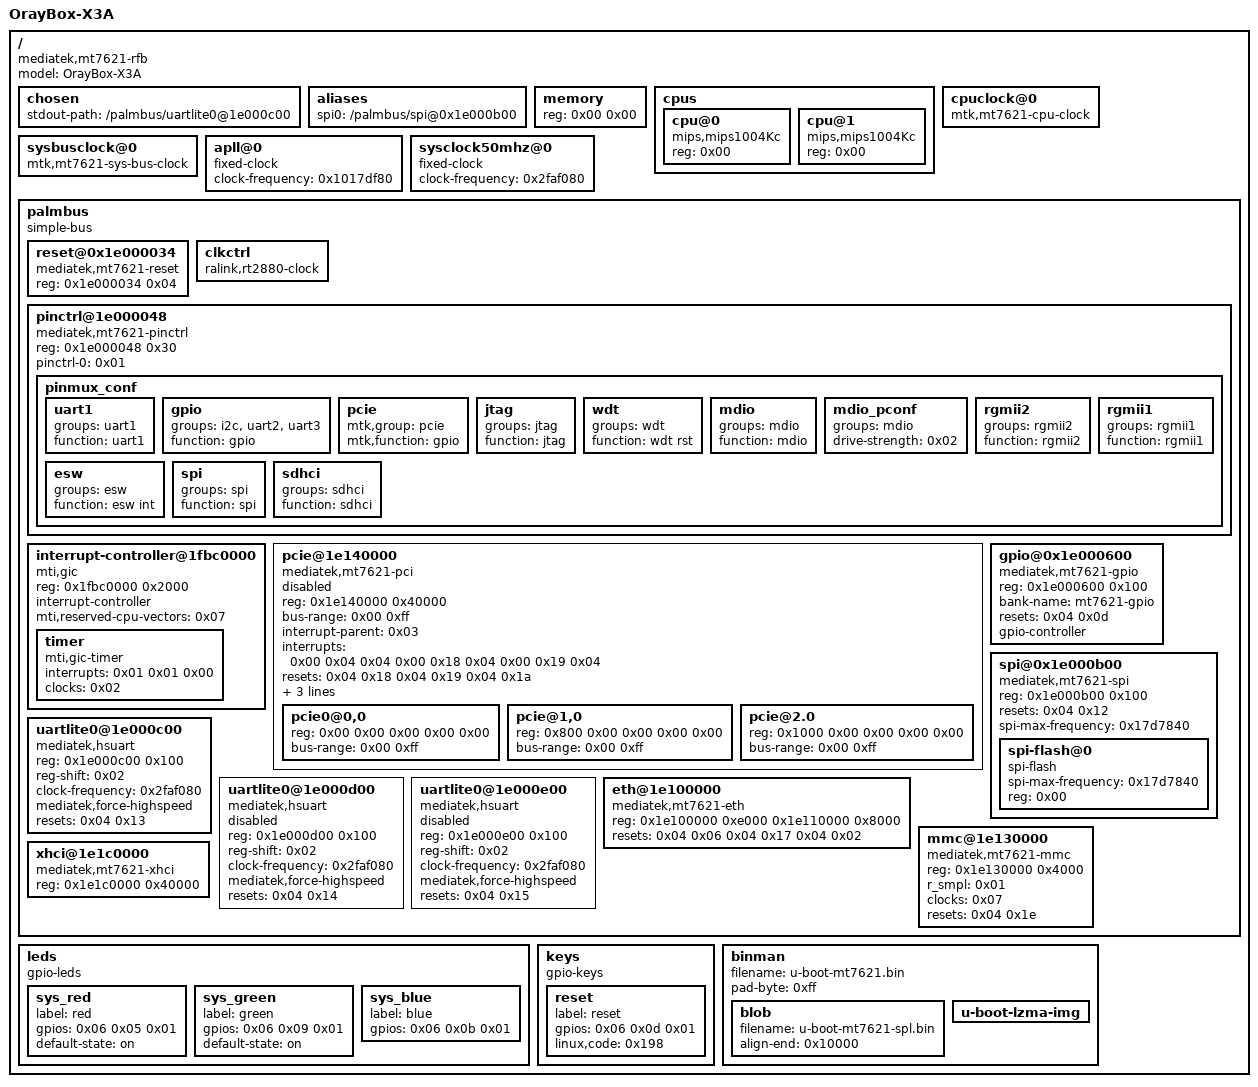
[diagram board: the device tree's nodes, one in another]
/dts-v1/;

/ {
	#address-cells = <0x01>;
	#size-cells = <0x01>;
	compatible = "mediatek,mt7621-rfb", "mediatek,mt7621-soc";
	model = "OrayBox-X3A";

	chosen {
		stdout-path = "/palmbus/uartlite0@1e000c00";
	};

	aliases {
		spi0 = "/palmbus/spi@0x1e000b00";
	};

	memory {
		device_type = "memory";
		reg = <0x00 0x00>;
	};

	cpus {
		#address-cells = <0x01>;
		#size-cells = <0x00>;

		cpu@0 {
			device_type = "cpu";
			compatible = "mips,mips1004Kc";
			reg = <0x00>;
		};

		cpu@1 {
			device_type = "cpu";
			compatible = "mips,mips1004Kc";
			reg = <0x00>;
		};
	};

	cpuclock@0 {
		#clock-cells = <0x00>;
		compatible = "mtk,mt7621-cpu-clock";
		phandle = <0x02>;
	};

	sysbusclock@0 {
		#clock-cells = <0x00>;
		compatible = "mtk,mt7621-sys-bus-clock";
	};

	apll@0 {
		#clock-cells = <0x00>;
		compatible = "fixed-clock";
		clock-frequency = <0x1017df80>;
	};

	sysclock50mhz@0 {
		compatible = "fixed-clock";
		clock-frequency = <0x2faf080>;
		#clock-cells = <0x00>;
		phandle = <0x07>;
	};

	palmbus {
		compatible = "simple-bus";
		ranges;
		#address-cells = <0x01>;
		#size-cells = <0x01>;

		reset@0x1e000034 {
			compatible = "mediatek,mt7621-reset";
			reg = <0x1e000034 0x04>;
			status = "okay";
			#reset-cells = <0x01>;
			phandle = <0x04>;
		};

		clkctrl {
			compatible = "ralink,rt2880-clock";
			#clock-cells = <0x01>;
			phandle = <0x05>;
		};

		pinctrl@1e000048 {
			compatible = "mediatek,mt7621-pinctrl";
			reg = <0x1e000048 0x30>;
			pinctrl-names = "default";
			pinctrl-0 = <0x01>;

			pinmux_conf {
				phandle = <0x01>;

				uart1 {
					groups = "uart1";
					function = "uart1";
				};

				gpio {
					groups = "i2c", "uart2", "uart3";
					function = "gpio";
				};

				pcie {
					mtk,group = "pcie";
					mtk,function = "gpio";
				};

				jtag {
					groups = "jtag";
					function = "jtag";
				};

				wdt {
					groups = "wdt";
					function = "wdt rst";
				};

				mdio {
					groups = "mdio";
					function = "mdio";
				};

				mdio_pconf {
					groups = "mdio";
					drive-strength = <0x02>;
				};

				rgmii2 {
					groups = "rgmii2";
					function = "rgmii2";
				};

				rgmii1 {
					groups = "rgmii1";
					function = "rgmii1";
				};

				esw {
					groups = "esw";
					function = "esw int";
				};

				spi {
					groups = "spi";
					function = "spi";
				};

				sdhci {
					groups = "sdhci";
					function = "sdhci";
				};
			};
		};

		interrupt-controller@1fbc0000 {
			compatible = "mti,gic";
			reg = <0x1fbc0000 0x2000>;
			interrupt-controller;
			#interrupt-cells = <0x03>;
			mti,reserved-cpu-vectors = <0x07>;
			phandle = <0x03>;

			timer {
				compatible = "mti,gic-timer";
				interrupts = <0x01 0x01 0x00>;
				clocks = <0x02>;
			};
		};

		pcie@1e140000 {
			compatible = "mediatek,mt7621-pci";
			reg = <0x1e140000 0x40000>;
			#address-cells = <0x03>;
			#size-cells = <0x02>;
			device_type = "pci";
			bus-range = <0x00 0xff>;
			ranges = <0x2000000 0x00 0x00 0x60000000 0x00 0x10000000 0x1000000 0x00 0x00 0x1e160000 0x00 0x10000>;
			interrupt-parent = <0x03>;
			interrupts = <0x00 0x04 0x04 0x00 0x18 0x04 0x00 0x19 0x04>;
			status = "disabled";
			resets = <0x04 0x18 0x04 0x19 0x04 0x1a>;
			reset-names = "pcie0", "pcie1", "pcie2";
			clocks = <0x05 0x18 0x05 0x19 0x05 0x1a>;
			clock-names = "pcie0", "pcie1", "pcie2";
			reset-gpios = <0x06 0x13 0x01>;
			reset-gpio-names = "pcie";

			pcie0@0,0 {
				reg = <0x00 0x00 0x00 0x00 0x00>;
				#address-cells = <0x03>;
				#size-cells = <0x02>;
				ranges;
				bus-range = <0x00 0xff>;
			};

			pcie@1,0 {
				reg = <0x800 0x00 0x00 0x00 0x00>;
				#address-cells = <0x03>;
				#size-cells = <0x02>;
				ranges;
				bus-range = <0x00 0xff>;
			};

			pcie@2.0 {
				reg = <0x1000 0x00 0x00 0x00 0x00>;
				#address-cells = <0x03>;
				#size-cells = <0x02>;
				ranges;
				bus-range = <0x00 0xff>;
			};
		};

		gpio@0x1e000600 {
			compatible = "mediatek,mt7621-gpio";
			reg = <0x1e000600 0x100>;
			bank-name = "mt7621-gpio";
			resets = <0x04 0x0d>;
			status = "okay";
			gpio-controller;
			#gpio-cells = <0x02>;
			phandle = <0x06>;
		};

		spi@0x1e000b00 {
			compatible = "mediatek,mt7621-spi";
			reg = <0x1e000b00 0x100>;
			resets = <0x04 0x12>;
			status = "okay";
			#address-cells = <0x01>;
			#size-cells = <0x00>;
			spi-max-frequency = <0x17d7840>;

			spi-flash@0 {
				#address-cells = <0x01>;
				#size-cells = <0x01>;
				compatible = "spi-flash";
				spi-max-frequency = <0x17d7840>;
				reg = <0x00>;
			};
		};

		uartlite0@1e000c00 {
			compatible = "mediatek,hsuart", "ns16550";
			reg = <0x1e000c00 0x100>;
			reg-shift = <0x02>;
			clock-frequency = <0x2faf080>;
			mediatek,force-highspeed;
			resets = <0x04 0x13>;
			status = "okay";
		};

		uartlite0@1e000d00 {
			compatible = "mediatek,hsuart", "ns16550";
			reg = <0x1e000d00 0x100>;
			reg-shift = <0x02>;
			clock-frequency = <0x2faf080>;
			mediatek,force-highspeed;
			resets = <0x04 0x14>;
			status = "disabled";
		};

		uartlite0@1e000e00 {
			compatible = "mediatek,hsuart", "ns16550";
			reg = <0x1e000e00 0x100>;
			reg-shift = <0x02>;
			clock-frequency = <0x2faf080>;
			mediatek,force-highspeed;
			resets = <0x04 0x15>;
			status = "disabled";
		};

		eth@1e100000 {
			compatible = "mediatek,mt7621-eth";
			reg = <0x1e100000 0xe000 0x1e110000 0x8000>;
			reg-names = "fe", "gmac";
			resets = <0x04 0x06 0x04 0x17 0x04 0x02>;
			reset-names = "fe", "gsw", "mcm";
			status = "okay";
			#address-cells = <0x01>;
			#size-cells = <0x00>;
		};

		mmc@1e130000 {
			compatible = "mediatek,mt7621-mmc";
			reg = <0x1e130000 0x4000>;
			r_smpl = <0x01>;
			clocks = <0x07>;
			clock-names = "source";
			resets = <0x04 0x1e>;
			status = "okay";
		};

		xhci@1e1c0000 {
			compatible = "mediatek,mt7621-xhci";
			reg = <0x1e1c0000 0x40000>;
			status = "okay";
			#address-cells = <0x01>;
			#size-cells = <0x00>;
		};
	};

	leds {
		compatible = "gpio-leds";

		sys_red {
			label = "red";
			gpios = <0x06 0x05 0x01>;
			default-state = "on";
		};

		sys_green {
			label = "green";
			gpios = <0x06 0x09 0x01>;
			default-state = "on";
		};

		sys_blue {
			label = "blue";
			gpios = <0x06 0x0b 0x01>;
		};
	};

	keys {
		compatible = "gpio-keys";

		reset {
			label = "reset";
			gpios = <0x06 0x0d 0x01>;
			linux,code = <0x198>;
		};
	};

	binman {
		filename = "u-boot-mt7621.bin";
		pad-byte = <0xff>;

		blob {
			filename = "u-boot-mt7621-spl.bin";
			align-end = <0x10000>;
		};

		u-boot-lzma-img {
		};
	};
};
